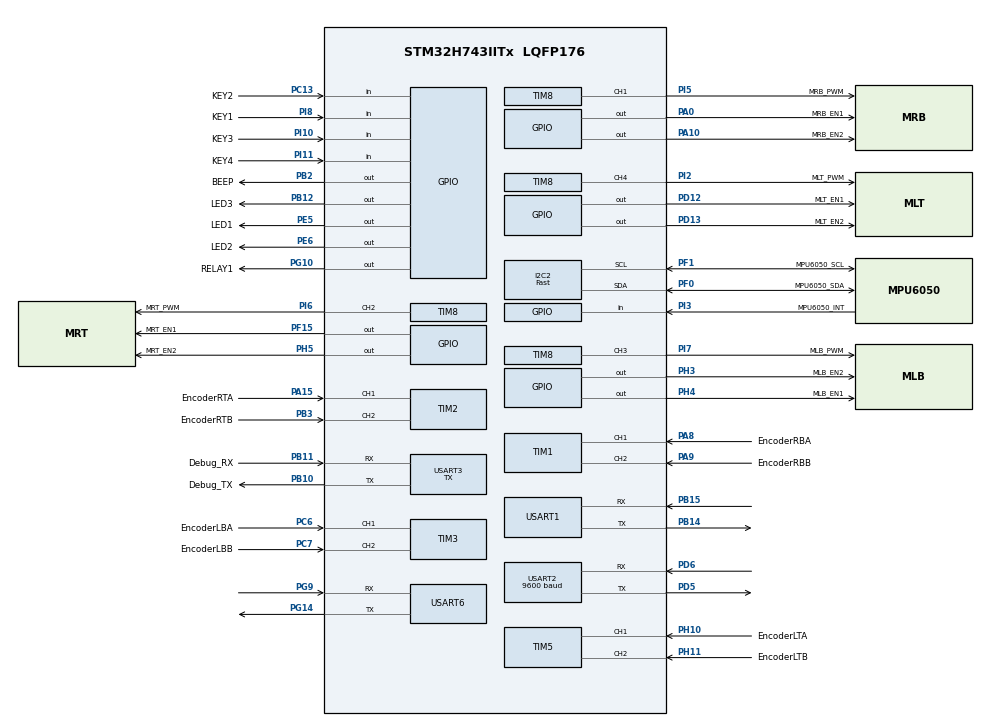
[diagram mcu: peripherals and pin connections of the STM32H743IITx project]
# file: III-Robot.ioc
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CORTEX_M7.CPU_DCache=Enabled
CORTEX_M7.CPU_ICache=Enabled
Dma.Request0=USART6_RX
Dma.USART6_RX.0.Direction=DMA_PERIPH_TO_MEMORY
Dma.USART6_RX.0.EventEnable=DISABLE
Dma.USART6_RX.0.FIFOMode=DMA_FIFOMODE_DISABLE
Dma.USART6_RX.0.Instance=DMA1_Stream0
Dma.USART6_RX.0.MemDataAlignment=DMA_MDATAALIGN_BYTE
Dma.USART6_RX.0.MemInc=DMA_MINC_ENABLE
Dma.USART6_RX.0.Mode=DMA_NORMAL
Dma.USART6_RX.0.PeriphDataAlignment=DMA_PDATAALIGN_BYTE
Dma.USART6_RX.0.PeriphInc=DMA_PINC_DISABLE
Dma.USART6_RX.0.Polarity=HAL_DMAMUX_REQ_GEN_RISING
Dma.USART6_RX.0.Priority=DMA_PRIORITY_LOW
Dma.USART6_RX.0.RequestNumber=1
Dma.USART6_RX.0.SignalID=NONE
Dma.USART6_RX.0.SyncEnable=DISABLE
Dma.USART6_RX.0.SyncPolarity=HAL_DMAMUX_SYNC_NO_EVENT
Dma.USART6_RX.0.SyncRequestNumber=1
Dma.USART6_RX.0.SyncSignalID=NONE
FREERTOS.Tasks01=defaultTask,47,128,StartDefaultTask,Default,NULL,Dynamic,NULL,NULL
FREERTOS.configLIBRARY_MAX_SYSCALL_INTERRUPT_PRIORITY=1
FREERTOS.configUSE_NEWLIB_REENTRANT=0
I2C2.I2C_Fall_Time=0
I2C2.I2C_Speed_Mode=I2C_Fast
I2C2.Speed=400
I2C2.Timing=0x009034B6
Mcu.Family=STM32H7
Mcu.Name=STM32H743IITx
Mcu.Package=LQFP176
NVIC.DMA1_Stream0_IRQn=true\:1\:0\:false\:false\:true\:true\:false\:true\:true
NVIC.PriorityGroup=NVIC_PRIORITYGROUP_4
NVIC.TIM17_IRQn=true\:0\:0\:false\:false\:true\:false\:false\:true\:true
NVIC.TIM1_UP_IRQn=true\:1\:0\:false\:false\:true\:true\:true\:true\:true
NVIC.TIM2_IRQn=true\:1\:0\:false\:false\:true\:true\:true\:true\:true
NVIC.TIM3_IRQn=true\:1\:0\:false\:false\:true\:true\:true\:true\:true
NVIC.TIM5_IRQn=true\:1\:0\:false\:false\:true\:true\:true\:true\:true
NVIC.TimeBase=TIM17_IRQn
NVIC.TimeBaseIP=TIM17
NVIC.USART1_IRQn=true\:1\:0\:false\:false\:false\:true\:true\:true\:true
NVIC.USART2_IRQn=true\:1\:0\:true\:false\:false\:true\:true\:true\:true
NVIC.USART6_IRQn=true\:1\:0\:false\:false\:true\:true\:true\:true\:true
PA0.GPIO_Label=MRB_EN1
PA0.GPIO_PuPd=GPIO_PULLUP
PA0.GPIO_Speed=GPIO_SPEED_FREQ_VERY_HIGH
PA0.Signal=GPIO_Output
PA10.GPIO_Label=MRB_EN2
PA10.GPIO_PuPd=GPIO_PULLUP
PA10.GPIO_Speed=GPIO_SPEED_FREQ_VERY_HIGH
PA10.Signal=GPIO_Output
PA15\ (JTDI).GPIO_Label=EncoderRTA
PA15\ (JTDI).GPIO_PuPd=GPIO_PULLUP
PA15\ (JTDI).Signal=S_TIM2_CH1_ETR
PA8.GPIO_Label=EncoderRBA
PA8.GPIO_PuPd=GPIO_PULLUP
PA8.Signal=S_TIM1_CH1
PA9.GPIO_Label=EncoderRBB
PA9.GPIO_PuPd=GPIO_PULLUP
PA9.Signal=S_TIM1_CH2
PB10.GPIO_Label=Debug_TX
PB10.GPIO_PuPd=GPIO_PULLUP
PB10.Mode=Asynchronous
PB10.Signal=USART3_TX
PB11.GPIO_Label=Debug_RX
PB11.GPIO_PuPd=GPIO_PULLUP
PB11.Mode=Asynchronous
PB11.Signal=USART3_RX
PB12.GPIO_Label=LED3
PB12.GPIO_PuPd=GPIO_PULLUP
PB12.GPIO_Speed=GPIO_SPEED_FREQ_VERY_HIGH
PB12.Signal=GPIO_Output
PB14.Mode=Asynchronous
PB14.Signal=USART1_TX
PB15.Mode=Asynchronous
PB15.Signal=USART1_RX
PB2.GPIO_Label=BEEP
PB2.GPIO_PuPd=GPIO_PULLUP
PB2.GPIO_Speed=GPIO_SPEED_FREQ_VERY_HIGH
PB2.PinState=GPIO_PIN_RESET
PB2.Signal=GPIO_Output
PB3\ (JTDO/TRACESWO).GPIO_Label=EncoderRTB
PB3\ (JTDO/TRACESWO).GPIO_PuPd=GPIO_PULLUP
PB3\ (JTDO/TRACESWO).Signal=S_TIM2_CH2
PC13.GPIO_Label=KEY2
PC13.GPIO_PuPd=GPIO_PULLUP
PC13.Signal=GPIO_Input
PC6.GPIO_Label=EncoderLBA
PC6.GPIO_PuPd=GPIO_PULLUP
PC6.Signal=S_TIM3_CH1
PC7.GPIO_Label=EncoderLBB
PC7.GPIO_PuPd=GPIO_PULLUP
PC7.Signal=S_TIM3_CH2
PD12.GPIO_Label=MLT_EN1
PD12.GPIO_PuPd=GPIO_PULLUP
PD12.GPIO_Speed=GPIO_SPEED_FREQ_VERY_HIGH
PD12.Signal=GPIO_Output
PD13.GPIO_Label=MLT_EN2
PD13.GPIO_PuPd=GPIO_PULLUP
PD13.GPIO_Speed=GPIO_SPEED_FREQ_VERY_HIGH
PD13.Signal=GPIO_Output
PD5.GPIO_PuPd=GPIO_PULLUP
PD5.Mode=Asynchronous
PD5.Signal=USART2_TX
PD6.GPIO_PuPd=GPIO_PULLUP
PD6.Mode=Asynchronous
PD6.Signal=USART2_RX
PE5.GPIO_Label=LED1
PE5.GPIO_PuPd=GPIO_PULLUP
PE5.GPIO_Speed=GPIO_SPEED_FREQ_VERY_HIGH
PE5.Signal=GPIO_Output
PE6.GPIO_Label=LED2
PE6.GPIO_PuPd=GPIO_PULLUP
PE6.GPIO_Speed=GPIO_SPEED_FREQ_VERY_HIGH
PE6.Signal=GPIO_Output
PF0.GPIO_Label=MPU6050_SDA
PF0.Mode=I2C
PF0.Signal=I2C2_SDA
PF1.GPIO_Label=MPU6050_SCL
PF1.Mode=I2C
PF1.Signal=I2C2_SCL
PF15.GPIO_Label=MRT_EN1
PF15.GPIO_PuPd=GPIO_PULLUP
PF15.GPIO_Speed=GPIO_SPEED_FREQ_VERY_HIGH
PF15.Signal=GPIO_Output
PG10.GPIO_Label=RELAY1
PG10.GPIO_PuPd=GPIO_PULLUP
PG10.GPIO_Speed=GPIO_SPEED_FREQ_HIGH
PG10.Signal=GPIO_Output
PG14.Mode=Asynchronous
PG14.Signal=USART6_TX
PG9.Mode=Asynchronous
PG9.Signal=USART6_RX
PH0-OSC_IN\ (PH0).Mode=HSE-External-Oscillator
PH0-OSC_IN\ (PH0).Signal=RCC_OSC_IN
PH1-OSC_OUT\ (PH1).Mode=HSE-External-Oscillator
PH1-OSC_OUT\ (PH1).Signal=RCC_OSC_OUT
PH10.GPIO_Label=EncoderLTA
PH10.GPIO_PuPd=GPIO_PULLUP
PH10.Signal=S_TIM5_CH1
PH11.GPIO_Label=EncoderLTB
PH11.GPIO_PuPd=GPIO_PULLUP
PH11.Signal=S_TIM5_CH2
PH3.GPIO_Label=MLB_EN2
PH3.GPIO_PuPd=GPIO_PULLUP
PH3.GPIO_Speed=GPIO_SPEED_FREQ_VERY_HIGH
PH3.Signal=GPIO_Output
PH4.GPIO_Label=MLB_EN1
PH4.GPIO_PuPd=GPIO_PULLUP
PH4.GPIO_Speed=GPIO_SPEED_FREQ_VERY_HIGH
PH4.Signal=GPIO_Output
PH5.GPIO_Label=MRT_EN2
PH5.GPIO_PuPd=GPIO_PULLUP
PH5.GPIO_Speed=GPIO_SPEED_FREQ_VERY_HIGH
PH5.Signal=GPIO_Output
PI10.GPIO_Label=KEY3
PI10.GPIO_PuPd=GPIO_PULLUP
PI10.Signal=GPIO_Input
PI11.GPIO_Label=KEY4
PI11.GPIO_PuPd=GPIO_PULLUP
PI11.Signal=GPIO_Input
PI2.GPIO_Label=MLT_PWM
PI2.GPIO_PuPd=GPIO_PULLUP
PI2.GPIO_Speed=GPIO_SPEED_FREQ_VERY_HIGH
PI2.Signal=S_TIM8_CH4
PI3.GPIO_Label=MPU6050_INT
PI3.GPIO_PuPd=GPIO_PULLDOWN
PI3.Signal=GPIO_Input
PI5.GPIO_Label=MRB_PWM
PI5.GPIO_PuPd=GPIO_PULLUP
PI5.GPIO_Speed=GPIO_SPEED_FREQ_VERY_HIGH
PI5.Signal=S_TIM8_CH1
PI6.GPIO_Label=MRT_PWM
PI6.GPIO_PuPd=GPIO_PULLUP
PI6.GPIO_Speed=GPIO_SPEED_FREQ_VERY_HIGH
PI6.Signal=S_TIM8_CH2
PI7.GPIO_Label=MLB_PWM
PI7.GPIO_PuPd=GPIO_PULLUP
PI7.GPIO_Speed=GPIO_SPEED_FREQ_VERY_HIGH
PI7.Signal=S_TIM8_CH3
PI8.GPIO_Label=KEY1
PI8.GPIO_PuPd=GPIO_PULLUP
PI8.Signal=GPIO_Input
ProjectManager.HeapSize=0x400
ProjectManager.StackSize=0x1000
ProjectManager.TargetToolchain=MDK-ARM V5.27
RCC.ADCFreq_Value=50390625
RCC.APB1Freq_Value=100000000
RCC.APB2Freq_Value=100000000
RCC.APB3Freq_Value=100000000
RCC.APB4Freq_Value=100000000
RCC.CortexFreq_Value=400000000
RCC.D1PPRE=RCC_APB3_DIV2
RCC.D2PPRE1=RCC_APB1_DIV2
RCC.D2PPRE2=RCC_APB2_DIV2
RCC.D3PPRE=RCC_APB4_DIV2
RCC.DIVM1=2
RCC.DIVN1=64
RCC.HCLKFreq_Value=200000000
RCC.HPRE=RCC_HCLK_DIV2
RCC.PLL2FRACN=0
RCC.PLL3FRACN=0
RCC.PLLFRACN=0
RCC.PLLSourceVirtual=RCC_PLLSOURCE_HSE
RCC.SYSCLKFreq_VALUE=400000000
RCC.SYSCLKSource=RCC_SYSCLKSOURCE_PLLCLK
RCC.USBFreq_Value=400000000
SH.S_TIM1_CH1.0=TIM1_CH1,Encoder_Interface
SH.S_TIM1_CH2.0=TIM1_CH2,Encoder_Interface
SH.S_TIM2_CH1_ETR.0=TIM2_CH1,Encoder_Interface
SH.S_TIM2_CH2.0=TIM2_CH2,Encoder_Interface
SH.S_TIM3_CH1.0=TIM3_CH1,Encoder_Interface
SH.S_TIM3_CH2.0=TIM3_CH2,Encoder_Interface
SH.S_TIM5_CH1.0=TIM5_CH1,Encoder_Interface
SH.S_TIM5_CH2.0=TIM5_CH2,Encoder_Interface
SH.S_TIM8_CH1.0=TIM8_CH1,PWM Generation1 CH1
SH.S_TIM8_CH2.0=TIM8_CH2,PWM Generation2 CH2
SH.S_TIM8_CH3.0=TIM8_CH3,PWM Generation3 CH3
SH.S_TIM8_CH4.0=TIM8_CH4,PWM Generation4 CH4
TIM1.AutoReloadPreload=TIM_AUTORELOAD_PRELOAD_ENABLE
TIM1.EncoderMode=TIM_ENCODERMODE_TI12
TIM1.IC1Filter=10
TIM1.IC2Filter=10
TIM2.AutoReloadPreload=TIM_AUTORELOAD_PRELOAD_ENABLE
TIM2.EncoderMode=TIM_ENCODERMODE_TI12
TIM2.IC1Filter=10
TIM2.IC2Filter=10
TIM3.AutoReloadPreload=TIM_AUTORELOAD_PRELOAD_ENABLE
TIM3.EncoderMode=TIM_ENCODERMODE_TI12
TIM3.IC1Filter=10
TIM3.IC2Filter=10
TIM5.AutoReloadPreload=TIM_AUTORELOAD_PRELOAD_ENABLE
TIM5.EncoderMode=TIM_ENCODERMODE_TI12
TIM5.IC1Filter=10
TIM5.IC2Filter=10
TIM8.AutoReloadPreload=TIM_AUTORELOAD_PRELOAD_ENABLE
TIM8.Channel-PWM\ Generation1\ CH1=TIM_CHANNEL_1
TIM8.Channel-PWM\ Generation2\ CH2=TIM_CHANNEL_2
TIM8.Channel-PWM\ Generation3\ CH3=TIM_CHANNEL_3
TIM8.Channel-PWM\ Generation4\ CH4=TIM_CHANNEL_4
TIM8.Period=1000-1
TIM8.Prescaler=20-1
TIM8.Pulse-PWM\ Generation1\ CH1=500
TIM8.Pulse-PWM\ Generation2\ CH2=500
TIM8.Pulse-PWM\ Generation3\ CH3=500
TIM8.Pulse-PWM\ Generation4\ CH4=500
USART1.VirtualMode-Asynchronous=VM_ASYNC
USART2.BaudRate=9600
USART2.VirtualMode-Asynchronous=VM_ASYNC
USART3.Mode=MODE_TX
USART3.VirtualMode-Asynchronous=VM_ASYNC
USART6.VirtualMode-Asynchronous=VM_ASYNC
VP_FREERTOS_VS_CMSIS_V2.Mode=CMSIS_V2
VP_SYS_VS_tim17.Mode=TIM17
VP_TIM8_VS_ClockSourceINT.Mode=Internal
board=custom

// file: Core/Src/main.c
/* USER CODE BEGIN Header */
/**
  ******************************************************************************
  * @file           : main.c
  * @brief          : Main program body
  ******************************************************************************
  * @attention
  *
  * <h2><center>&copy; Copyright (c) 2023 STMicroelectronics.
  * All rights reserved.</center></h2>
  *
  * This software component is licensed by ST under Ultimate Liberty license
  * SLA0044, the "License"; You may not use this file except in compliance with
  * the License. You may obtain a copy of the License at:
  *                             www.st.com/SLA0044
  *
  ******************************************************************************
  */
/* USER CODE END Header */
#include "main.h"
#include "cmsis_os.h"
#include "dma.h"
#include "i2c.h"
#include "tim.h"
#include "usart.h"
#include "gpio.h"

void SystemClock_Config(void);
void MX_FREERTOS_Init(void);

int main(void)
{

  /* Enable I-Cache---------------------------------------------------------*/
  SCB_EnableICache();

  /* Enable D-Cache---------------------------------------------------------*/
  SCB_EnableDCache();

  /* MCU Configuration--------------------------------------------------------*/

  /* Reset of all peripherals, Initializes the Flash interface and the Systick. */
  HAL_Init();

  /* Configure the system clock */
  SystemClock_Config();

  /* Initialize all configured peripherals */
  MX_GPIO_Init();
  MX_DMA_Init();
  MX_TIM3_Init();
  MX_TIM5_Init();
  MX_TIM8_Init();
  MX_I2C2_Init();
  MX_USART3_UART_Init();
  MX_TIM1_Init();
  MX_TIM2_Init();
  MX_USART2_UART_Init();
  MX_USART6_UART_Init();
  MX_USART1_UART_Init();

  /* Init scheduler */
  osKernelInitialize();  /* Call init function for freertos objects (in freertos.c) */
  MX_FREERTOS_Init();

  /* Start scheduler */
  osKernelStart();
  /* We should never get here as control is now taken by the scheduler */
  /* Infinite loop */
  /* USER CODE BEGIN WHILE */
  while (1)
  {
	  osDelay(100);
    /* USER CODE END WHILE */

  }
}

void SystemClock_Config(void)
{
  RCC_OscInitTypeDef RCC_OscInitStruct = {0};
  RCC_ClkInitTypeDef RCC_ClkInitStruct = {0};

  /** Supply configuration update enable
  */
  HAL_PWREx_ConfigSupply(PWR_LDO_SUPPLY);

  /** Configure the main internal regulator output voltage
  */
  __HAL_PWR_VOLTAGESCALING_CONFIG(PWR_REGULATOR_VOLTAGE_SCALE1);

  while(!__HAL_PWR_GET_FLAG(PWR_FLAG_VOSRDY)) {}

  /** Initializes the RCC Oscillators according to the specified parameters
  * in the RCC_OscInitTypeDef structure.
  */
  RCC_OscInitStruct.OscillatorType = RCC_OSCILLATORTYPE_HSE;
  RCC_OscInitStruct.HSEState = RCC_HSE_ON;
  RCC_OscInitStruct.PLL.PLLState = RCC_PLL_ON;
  RCC_OscInitStruct.PLL.PLLSource = RCC_PLLSOURCE_HSE;
  RCC_OscInitStruct.PLL.PLLM = 2;
  RCC_OscInitStruct.PLL.PLLN = 64;
  RCC_OscInitStruct.PLL.PLLP = 2;
  RCC_OscInitStruct.PLL.PLLQ = 2;
  RCC_OscInitStruct.PLL.PLLR = 2;
  RCC_OscInitStruct.PLL.PLLRGE = RCC_PLL1VCIRANGE_3;
  RCC_OscInitStruct.PLL.PLLVCOSEL = RCC_PLL1VCOWIDE;
  RCC_OscInitStruct.PLL.PLLFRACN = 0;
  if (HAL_RCC_OscConfig(&RCC_OscInitStruct) != HAL_OK)
  {
    Error_Handler();
  }

  /** Initializes the CPU, AHB and APB buses clocks
  */
  RCC_ClkInitStruct.ClockType = RCC_CLOCKTYPE_HCLK|RCC_CLOCKTYPE_SYSCLK
                              |RCC_CLOCKTYPE_PCLK1|RCC_CLOCKTYPE_PCLK2
                              |RCC_CLOCKTYPE_D3PCLK1|RCC_CLOCKTYPE_D1PCLK1;
  RCC_ClkInitStruct.SYSCLKSource = RCC_SYSCLKSOURCE_PLLCLK;
  RCC_ClkInitStruct.SYSCLKDivider = RCC_SYSCLK_DIV1;
  RCC_ClkInitStruct.AHBCLKDivider = RCC_HCLK_DIV2;
  RCC_ClkInitStruct.APB3CLKDivider = RCC_APB3_DIV2;
  RCC_ClkInitStruct.APB1CLKDivider = RCC_APB1_DIV2;
  RCC_ClkInitStruct.APB2CLKDivider = RCC_APB2_DIV2;
  RCC_ClkInitStruct.APB4CLKDivider = RCC_APB4_DIV2;

  if (HAL_RCC_ClockConfig(&RCC_ClkInitStruct, FLASH_LATENCY_2) != HAL_OK)
  {
    Error_Handler();
  }
}

void HAL_TIM_PeriodElapsedCallback(TIM_HandleTypeDef *htim)
{
  if (htim->Instance == TIM17) {
    HAL_IncTick();
  }
}

void Error_Handler(void)
{
  __disable_irq();
  while (1)
  {
  }
}

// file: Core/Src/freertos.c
/* USER CODE BEGIN Header */
/**
  ******************************************************************************
  * File Name          : freertos.c
  * Description        : Code for freertos applications
  ******************************************************************************
  * @attention
  *
  * <h2><center>&copy; Copyright (c) 2023 STMicroelectronics.
  * All rights reserved.</center></h2>
  *
  * This software component is licensed by ST under Ultimate Liberty license
  * SLA0044, the "License"; You may not use this file except in compliance with
  * the License. You may obtain a copy of the License at:
  *                             www.st.com/SLA0044
  *
  ******************************************************************************
  */
/* USER CODE END Header */

#include "FreeRTOS.h"
#include "task.h"
#include "main.h"
#include "cmsis_os.h"

/* USER CODE BEGIN Includes */
#include "task_led.h"
#include "task_key.h"
#include "task_robot.h"
#include "task_bat.h"
#include "task_imu.h"
#include "task_protocol.h"
/* USER CODE END Includes */

/* Definitions for defaultTask */
osThreadId_t defaultTaskHandle;
const osThreadAttr_t defaultTask_attributes = {
  .name = "defaultTask",
  .stack_size = 128 * 4,
  .priority = (osPriority_t) osPriorityHigh7,
};

void StartDefaultTask(void *argument);

void MX_FREERTOS_Init(void); /* (MISRA C 2004 rule 8.1) */

void MX_FREERTOS_Init(void) {

  /* Create the thread(s) */
  /* creation of defaultTask */
  defaultTaskHandle = osThreadNew(StartDefaultTask, NULL, &defaultTask_attributes);

  /* USER CODE BEGIN RTOS_THREADS */
  /* add threads, ... */
  vTaskSuspendAll();
  create_led_thread();
//  create_key_thread();
  create_robot_thread();
//  create_bat_thread();
//  create_imu_thread();
  create_protocol_thread();
  xTaskResumeAll();
  /* USER CODE END RTOS_THREADS */

}

void StartDefaultTask(void *argument)
{
  /* USER CODE BEGIN StartDefaultTask */
  /* Infinite loop */
	vTaskDelete(NULL);
  /* USER CODE END StartDefaultTask */
}
